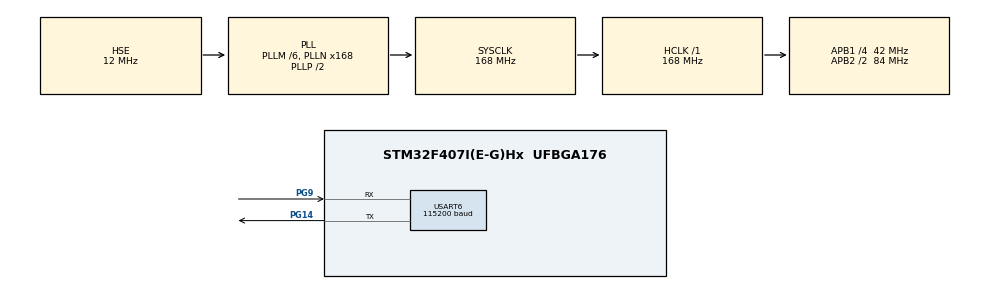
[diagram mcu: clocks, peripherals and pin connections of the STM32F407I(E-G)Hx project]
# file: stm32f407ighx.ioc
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Mcu.Family=STM32F4
Mcu.Name=STM32F407I(E-G)Hx
Mcu.Package=UFBGA176
NVIC.PriorityGroup=NVIC_PRIORITYGROUP_4
NVIC.TIM7_IRQn=true\:0\:0\:true\:false\:true\:false\:true\:true
NVIC.TimeBase=TIM7_IRQn
NVIC.TimeBaseIP=TIM7
NVIC.USART6_IRQn=true\:5\:0\:true\:false\:true\:true\:true\:true
PA13.Mode=Serial_Wire
PA13.Signal=SYS_JTMS-SWDIO
PA14.Mode=Serial_Wire
PA14.Signal=SYS_JTCK-SWCLK
PG14.Mode=Asynchronous
PG14.Signal=USART6_TX
PG9.Mode=Asynchronous
PG9.Signal=USART6_RX
PH0-OSC_IN.Mode=HSE-External-Oscillator
PH0-OSC_IN.Signal=RCC_OSC_IN
PH1-OSC_OUT.Mode=HSE-External-Oscillator
PH1-OSC_OUT.Signal=RCC_OSC_OUT
ProjectManager.HeapSize=0x2000
ProjectManager.StackSize=0x2000
ProjectManager.TargetToolchain=CMake
RCC.48MHZClocksFreq_Value=48000000
RCC.AHBFreq_Value=168000000
RCC.APB1CLKDivider=RCC_HCLK_DIV4
RCC.APB1Freq_Value=42000000
RCC.APB1TimFreq_Value=84000000
RCC.APB2CLKDivider=RCC_HCLK_DIV2
RCC.APB2Freq_Value=84000000
RCC.APB2TimFreq_Value=168000000
RCC.CortexFreq_Value=168000000
RCC.HCLKFreq_Value=168000000
RCC.HSE_VALUE=12000000
RCC.HSI_VALUE=16000000
RCC.LSE_VALUE=32768
RCC.PLLM=6
RCC.PLLN=168
RCC.PLLQ=7
RCC.PLLSourceVirtual=RCC_PLLSOURCE_HSE
RCC.SYSCLKFreq_VALUE=168000000
RCC.SYSCLKSource=RCC_SYSCLKSOURCE_PLLCLK
RCC.VCOOutputFreq_Value=336000000
STMicroelectronics.X-CUBE-ALGOBUILD.1.4.0.LibraryCcDSPOoLibraryJjDSPOoLibrary=true
USART6.BaudRate=115200
USART6.Mode=MODE_TX
USART6.VirtualMode=VM_ASYNC
VP_STMicroelectronics.X-CUBE-ALGOBUILD_VS_DSPOoLibraryJjLibrary_1.4.0_1.4.0.Mode=DSPOoLibraryJjLibrary
VP_SYS_VS_tim7.Mode=TIM7
board=custom

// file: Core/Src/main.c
/* USER CODE BEGIN Header */
/**
  ******************************************************************************
  * @file           : main.c
  * @brief          : Main program body
  ******************************************************************************
  * @attention
  *
  * Copyright (c) 2025 STMicroelectronics.
  * All rights reserved.
  *
  * This software is licensed under terms that can be found in the LICENSE file
  * in the root directory of this software component.
  * If no LICENSE file comes with this software, it is provided AS-IS.
  *
  ******************************************************************************
  */
/* USER CODE END Header */
#include "main.h"
#include "usart.h"
#include "gpio.h"

/* USER CODE BEGIN Includes */

#include "FreeRTOS.h"
#include "task.h"

/* USER CODE END Includes */

void SystemClock_Config(void);
/* USER CODE BEGIN PFP */

extern void freeRtosInit(void);

/* USER CODE END PFP */

int main(void)
{

  /* MCU Configuration--------------------------------------------------------*/

  /* Reset of all peripherals, Initializes the Flash interface and the Systick. */
  HAL_Init();

  /* Configure the system clock */
  SystemClock_Config();

  /* Initialize all configured peripherals */
  MX_GPIO_Init();
  MX_USART6_UART_Init();
  /* USER CODE BEGIN 2 */

  freeRtosInit();
  vTaskStartScheduler();

  /* USER CODE END 2 */

  /* Infinite loop */
  while (1)
  {

  }
}

void SystemClock_Config(void)
{
  RCC_OscInitTypeDef RCC_OscInitStruct = {0};
  RCC_ClkInitTypeDef RCC_ClkInitStruct = {0};

  /** Configure the main internal regulator output voltage
  */
  __HAL_RCC_PWR_CLK_ENABLE();
  __HAL_PWR_VOLTAGESCALING_CONFIG(PWR_REGULATOR_VOLTAGE_SCALE1);

  /** Initializes the RCC Oscillators according to the specified parameters
  * in the RCC_OscInitTypeDef structure.
  */
  RCC_OscInitStruct.OscillatorType = RCC_OSCILLATORTYPE_HSE;
  RCC_OscInitStruct.HSEState = RCC_HSE_ON;
  RCC_OscInitStruct.PLL.PLLState = RCC_PLL_ON;
  RCC_OscInitStruct.PLL.PLLSource = RCC_PLLSOURCE_HSE;
  RCC_OscInitStruct.PLL.PLLM = 6;
  RCC_OscInitStruct.PLL.PLLN = 168;
  RCC_OscInitStruct.PLL.PLLP = RCC_PLLP_DIV2;
  RCC_OscInitStruct.PLL.PLLQ = 7;
  if (HAL_RCC_OscConfig(&RCC_OscInitStruct) != HAL_OK)
  {
    Error_Handler();
  }

  /** Initializes the CPU, AHB and APB buses clocks
  */
  RCC_ClkInitStruct.ClockType = RCC_CLOCKTYPE_HCLK|RCC_CLOCKTYPE_SYSCLK
                              |RCC_CLOCKTYPE_PCLK1|RCC_CLOCKTYPE_PCLK2;
  RCC_ClkInitStruct.SYSCLKSource = RCC_SYSCLKSOURCE_PLLCLK;
  RCC_ClkInitStruct.AHBCLKDivider = RCC_SYSCLK_DIV1;
  RCC_ClkInitStruct.APB1CLKDivider = RCC_HCLK_DIV4;
  RCC_ClkInitStruct.APB2CLKDivider = RCC_HCLK_DIV2;

  if (HAL_RCC_ClockConfig(&RCC_ClkInitStruct, FLASH_LATENCY_5) != HAL_OK)
  {
    Error_Handler();
  }
}

void HAL_TIM_PeriodElapsedCallback(TIM_HandleTypeDef *htim)
{
  if (htim->Instance == TIM7)
  {
    HAL_IncTick();
  }
}

void Error_Handler(void)
{
  __disable_irq();
  while (1)
  {
  }
}

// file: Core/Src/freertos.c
/* USER CODE BEGIN Header */
/**
  ******************************************************************************
  * File Name          : freertos.c
  * Description        : Code for freertos applications
  ******************************************************************************
  * @attention
  *
  * Copyright (c) 2025 STMicroelectronics.
  * All rights reserved.
  *
  * This software is licensed under terms that can be found in the LICENSE file
  * in the root directory of this software component.
  * If no LICENSE file comes with this software, it is provided AS-IS.
  *
  ******************************************************************************
  */
/* USER CODE END Header */

#include "FreeRTOS.h"
#include "task.h"
#include "main.h"
#include "cmsis_os.h"

/* USER CODE BEGIN Includes */

#include "emdevif/attributes_and_useful_macros.h"
#include "rmdev_test_impl.h"

/* USER CODE END Includes */

typedef StaticTask_t osStaticThreadDef_t;

/* Definitions for defaultTask */
osThreadId_t defaultTaskHandle;
uint32_t defaultTaskBuffer[ 1024 ];
osStaticThreadDef_t defaultTaskControlBlock;
const osThreadAttr_t defaultTask_attributes = {
  .name = "defaultTask",
  .cb_mem = &defaultTaskControlBlock,
  .cb_size = sizeof(defaultTaskControlBlock),
  .stack_mem = &defaultTaskBuffer[0],
  .stack_size = sizeof(defaultTaskBuffer),
  .priority = (osPriority_t) osPriorityRealtime7,
};

void StartDefaultTask(void *argument);

void MX_FREERTOS_Init(void); /* (MISRA C 2004 rule 8.1) */

void MX_FREERTOS_Init(void) {

  /* Create the thread(s) */
  /* creation of defaultTask */
  defaultTaskHandle = osThreadNew(StartDefaultTask, NULL, &defaultTask_attributes);

}

/* USER CODE BEGIN Header_StartDefaultTask */
/**
  * @brief  Function implementing the defaultTask thread.
  * @param  argument: Not used
  * @retval None
  */
EMDEVIF_NO_RETURN
/* USER CODE END Header_StartDefaultTask */
void StartDefaultTask(void *argument)
{
  /* USER CODE BEGIN StartDefaultTask */

  EMDEVIF_UNUSED(argument);

  testEntry();

  /* Infinite loop */
  for(;;)
  {
    osDelay(1);
  }
  /* USER CODE END StartDefaultTask */
}
